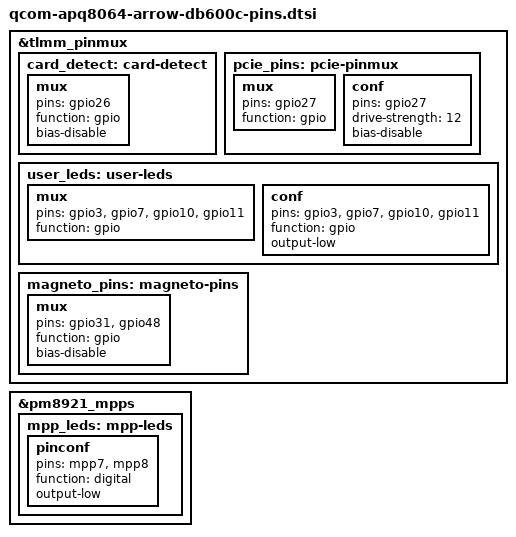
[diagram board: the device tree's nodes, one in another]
&tlmm_pinmux {
	card_detect: card-detect {
		mux {
			pins = "gpio26";
			function = "gpio";
			bias-disable;
		};
	};

	pcie_pins: pcie-pinmux {
		mux {
			pins = "gpio27";
			function = "gpio";
		};
		conf {
			pins = "gpio27";
			drive-strength = <12>;
			bias-disable;
		};
	};

	user_leds: user-leds {
		mux {
			pins = "gpio3", "gpio7", "gpio10", "gpio11";
			function = "gpio";
		};

		conf {
			pins = "gpio3", "gpio7", "gpio10", "gpio11";
			function = "gpio";
			output-low;
		};
	};

	magneto_pins: magneto-pins {
		mux {
			pins = "gpio31", "gpio48";
			function = "gpio";
			bias-disable;
		};
	};
};

&pm8921_mpps {
	mpp_leds: mpp-leds {
		pinconf {
			pins = "mpp7", "mpp8";
			function = "digital";
			output-low;
		};
	};
};
